AUTOSAR XML (schema 4-0-3)
package /ComponentTypes
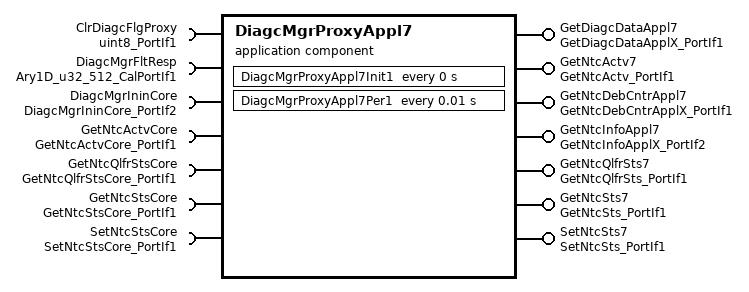
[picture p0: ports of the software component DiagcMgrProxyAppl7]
  application sw component type DiagcMgrProxyAppl7
    7 x provide port, all with server-com-spec{operation=Oper, queue-length=1}:
      GetDiagcDataAppl7: provided-interface=GetDiagcDataApplX_PortIf1
      GetNtcActv7: provided-interface=GetNtcActv_PortIf1
      GetNtcDebCntrAppl7: provided-interface=GetNtcDebCntrApplX_PortIf1
      GetNtcInfoAppl7: provided-interface=GetNtcInfoApplX_PortIf2
      GetNtcQlfrSts7: provided-interface=GetNtcQlfrSts_PortIf1
      GetNtcSts7: provided-interface=GetNtcSts_PortIf1
      SetNtcSts7: provided-interface=SetNtcSts_PortIf1
    7 x require port:
      ClrDiagcFlgProxy: nonqueued-receiver-com-spec{data-element=Val, filter=data-filter-type=ALWAYS, init-value=0}, required-interface=uint8_PortIf1
      DiagcMgrFltResp: parameter-require-com-spec{init-value=[0, 2147487488, 2147487488, 2147487488, 2147487488, 2147487488, 2147487488, 2147487488, 2147487488, 2147487488, 2147487488, 2147487488, 2147487488, 2147487488, 2147487488, 2147487488, 2147487488, 2147487488, 2147487488, 2147487488, 2147487488, 2147487488, 2147487488, 2147487488, 2147487488, 2147487488, 2147487488, 2147487488, 2147487488, 2147487488, 2147487488, 2147487488, 2147487488, 2147487488, 2147487488, 2147487488, 2147487488, 2147487488, 2147487488, 2147487488, 2147487488, 2147487488, 2147487488, 2147487488, 2147487488, 2147487488, 2147487488, 2147487488, 2147487488, 2147487488, 2147487488, 2147487488, 2147487488, 2147487488, 2147487488, 2147487488, 2147487488, 2147487488, 2147487488, 2147487488, 2147487488, 2147487488, 2147487488, 2147487488, 2147487488, 2147487488, 2147487488, 2147487488, 2147487488, 2147487488, 2147487488, 2147487488, 2147487488, 2147487488, 2147487488, 2147487488, 2147487488, 2147487488, 2147487488, 2147487488, 2147487488, 2147487488, 2147487488, 2147487488, 2147487488, 2147487488, 2147487488, 2147487488, 2147487488, 2147487488, 2147487488, 2147487488, 2147487488, 2147487488, 2147487488, 2147487488, 2147487488, 2147487488, 2147487488, 2147487488, 2147487488, 2147487488, 2147487488, 2147487488, 2147487488, 2147487488, 2147487488, 2147487488, 2147487488, 2147487488, 2147487488, 2147487488, 2147487488, 2147487488, 2147487488, 2147487488, 2147487488, 2147487488, 2147487488, 2147487488, 2147487488, 2147487488, 2147487488, 2147487488, 2147487488, 2147487488, 2147487488, 2147487488, 2147487488, 2147487488, 2147487488, 2147487488, 2147487488, 2147487488, 2147487488, 2147487488, 2147487488, 2147487488, 2147487488, 2147487488, 2147487488, 2147487488, 2147487488, 2147487488, 2147487488, 2147487488, 2147487488, 2147487488, 2147487488, 2147487488, 2147487488, 2147487488, 2147487488, 2147487488, 2147487488, 2147487488, 2147487488, 2147487488, 2147487488, 2147487488, 2147487488, 2147487488, 2147487488, 2147487488, 2147487488, 2147487488, 2147487488, 2147487488, 2147487488, 2147487488, 2147487488, 2147487488, 2147487488, 2147487488, 2147487488, 2147487488, 2147487488, 2147487488, 2147487488, 2147487488, 2147487488, 2147487488, 2147487488, 2147487488, 2147487488, 2147487488, 2147487488, 2147487488, 2147487488, 2147487488, 2147487488, 2147487488, 2147487488, 2147487488, 2147487488, 2147487488, 2147487488, 2147487488, 2147487488, 2147487488, 2147487488, 2147487488, 2147487488, 2147487488, 2147487488, 2147487488, 2147487488, 2147487488, 2147487488, 2147487488, 2147487488, 2147487488, 2147487488, 2147487488, 2147487488, 2147487488, 2147487488, 2147487488, 2147487488, 2147487488, 2147487488, 2147487488, 2147487488, 2147487488, 2147487488, 2147487488, 2147487488, 2147487488, 2147487488, 2147487488, 2147487488, 2147487488, 2147487488, 2147487488, 2147487488, 2147487488, 2147487488, 2147487488, 2147487488, 2147487488, 2147487488, 2147487488, 2147487488, 2147487488, 2147487488, 2147487488, 2147487488, 2147487488, 2147487488, 2147487488, 2147487488, 2147487488, 2147487488, 2147487488, 2147487488, 2147487488, 2147487488, 2147487488, 2147487488, 2147487488, 2147487488, 2147487488, 2147487488, 2147487488, 2147487488, 2147487488, 2147487488, 2147487488, 2147487488, 2147487488, 2147487488, 2147487488, 2147487488, 2147487488, 2147487488, 2147487488, 2147487488, 2147487488, 2147487488, 2147487488, 2147487488, 2147487488, 2147487488, 2147487488, 2147487488, 2147487488, 2147487488, 2147487488, 2147487488, 2147487488, 2147487488, 2147487488, 2147487488, 2147487488, 2147487488, 2147487488, 2147487488, 2147487488, 2147487488, 2147487488, 2147487488, 2147487488, 2147487488, 2147487488, 2147487488, 2147487488, 2147487488, 2147487488, 2147487488, 2147487488, 2147487488, 2147487488, 2147487488, 2147487488, 2147487488, 2147487488, 2147487488, 2147487488, 2147487488, 2147487488, 2147487488, 2147487488, 2147487488, 2147487488, 2147487488, 2147487488, 2147487488, 2147487488, 2147487488, 2147487488, 2147487488, 2147487488, 2147487488, 2147487488, 2147487488, 2147487488, 2147487488, 2147487488, 2147487488, 2147487488, 2147487488, 2147487488, 2147487488, 2147487488, 2147487488, 2147487488, 2147487488, 2147487488, 2147487488, 2147487488, 2147487488, 2147487488, 2147487488, 2147487488, 2147487488, 2147487488, 2147487488, 2147487488, 2147487488, 2147487488, 2147487488, 2147487488, 2147487488, 2147487488, 2147487488, 2147487488, 2147487488, 2147487488, 2147487488, 2147487488, 2147487488, 2147487488, 2147487488, 2147487488, 2147487488, 2147487488, 2147487488, 2147487488, 2147487488, 2147487488, 2147487488, 2147487488, 2147487488, 2147487488, 2147487488, 2147487488, 2147487488, 2147487488, 2147487488, 2147487488, 2147487488, 2147487488, 2147487488, 2147487488, 2147487488, 2147487488, 2147487488, 2147487488, 2147487488, 2147487488, 2147487488, 2147487488, 2147487488, 2147487488, 2147487488, 2147487488, 2147487488, 2147487488, 2147487488, 2147487488, 2147487488, 2147487488, 2147487488, 2147487488, 2147487488, 2147487488, 2147487488, 2147487488, 2147487488, 2147487488, 2147487488, 2147487488, 2147487488, 2147487488, 2147487488, 2147487488, 2147487488, 2147487488, 2147487488, 2147487488, 2147487488, 2147487488, 2147487488, 2147487488, 2147487488, 2147487488, 2147487488, 2147487488, 2147487488, 2147487488, 2147487488, 2147487488, 2147487488, 2147487488, 2147487488, 2147487488, 2147487488, 2147487488, 2147487488, 2147487488, 2147487488, 2147487488, 2147487488, 2147487488, 2147487488, 2147487488, 2147487488, 2147487488, 2147487488, 2147487488, 2147487488, 2147487488, 2147487488, 2147487488, 2147487488, 2147487488, 2147487488, 2147487488, 2147487488, 2147487488, 2147487488, 2147487488, 2147487488, 2147487488, 2147487488, 2147487488, 2147487488, 2147487488, 2147487488, 2147487488, 2147487488, 2147487488, 2147487488, 2147487488, 2147487488, 2147487488, 2147487488, 2147487488, 2147487488, 2147487488, 2147487488, 2147487488, 2147487488, 2147487488, 2147487488, 2147487488, 2147487488, 2147487488, 2147487488, 2147487488, 2147487488, 2147487488, 2147487488, 2147487488, 2147487488, 2147487488, 2147487488, 2147487488, 2147487488, 2147487488, 2147487488, 2147487488], parameter=Ary1D}, required-interface=Ary1D_u32_512_CalPortIf1
      DiagcMgrIninCore: required-interface=DiagcMgrIninCore_PortIf2
      GetNtcActvCore: required-interface=GetNtcActvCore_PortIf1
      GetNtcQlfrStsCore: required-interface=GetNtcQlfrStsCore_PortIf1
      GetNtcStsCore: required-interface=GetNtcStsCore_PortIf1
      SetNtcStsCore: required-interface=SetNtcStsCore_PortIf1
    behavior DiagcMgrProxyAppl7_InternalBehavior
      exclusive area DiagcMgrProxyAppl7
      ar-typed-per-instance-memorys:
        5 x data:
          DiagcData7: sw-calibration-access=READ-ONLY, type=DiagcDataRec1
          DiagcMgrNtcInfo7Ary: type=Ary1D_NtcInfoRec4_DiagcMgrProxyAppl7
          DiagcMgrNtcInfo7DebCntrAry: type=Ary1D_s16_DiagcMgrProxyAppl7
          PrevClrNtcFlg7: sw-calibration-access=READ-ONLY, type=uint8
          ProxySetNtcData7: sw-calibration-access=READ-ONLY, type=DiagcDataRec1
      timing event DiagcMgrProxyAppl7_InitEvent: start-on-event=DiagcMgrProxyAppl7Init1, period=0
      timing event TMT_DiagcMgrProxyAppl7Per1: start-on-event=DiagcMgrProxyAppl7Per1, period=0.01
      7 x operation invoked event:
        OIT_GetDiagcDataAppl7_Oper_GetDiagcDataAppl7_Oper: start-on-event=GetDiagcDataAppl7_Oper, operation=GetDiagcDataAppl7.Oper
        OIT_GetNtcActv7_Oper_GetNtcActv7_Oper: start-on-event=GetNtcActv7_Oper, operation=GetNtcActv7.Oper
        OIT_GetNtcDebCntrAppl7_Oper_GetNtcDebCntrAppl7_Oper: start-on-event=GetNtcDebCntrAppl7_Oper, operation=GetNtcDebCntrAppl7.Oper
        OIT_GetNtcInfoAppl7_Oper_GetNtcInfoAppl7_Oper: start-on-event=GetNtcInfoAppl7_Oper, operation=GetNtcInfoAppl7.Oper
        OIT_GetNtcQlfrSts7_Oper_GetNtcQlfrSts7_Oper: start-on-event=GetNtcQlfrSts7_Oper, operation=GetNtcQlfrSts7.Oper
        OIT_GetNtcSts7_Oper_GetNtcSts7_Oper: start-on-event=GetNtcSts7_Oper, operation=GetNtcSts7.Oper
        OIT_SetNtcSts7_Oper_SetNtcSts7_Oper: start-on-event=SetNtcSts7_Oper, operation=SetNtcSts7.Oper
      9 x runnable:
        DiagcMgrProxyAppl7Init1
          sync call SC_DiagcMgrIninCore_Oper: operation=DiagcMgrIninCore.Oper, timeout=0
        DiagcMgrProxyAppl7Per1: can-enter-exclusive-area=DiagcMgrProxyAppl7
          data-receive-point-by-arguments:
            access REC_ClrNtcFlg_Val: accessed-variable=ClrDiagcFlgProxy.Val
        GetDiagcDataAppl7_Oper
        GetNtcActv7_Oper: can-be-invoked-concurrently=true
          sync call SC_GetNtcActvCore_Oper: operation=GetNtcActvCore.Oper, timeout=0
        GetNtcDebCntrAppl7_Oper
        GetNtcInfoAppl7_Oper
        GetNtcQlfrSts7_Oper: can-be-invoked-concurrently=true
          sync call SC_GetNtcQlfrStsCore_Oper: operation=GetNtcQlfrStsCore.Oper, timeout=0
        GetNtcSts7_Oper: can-be-invoked-concurrently=true
          sync call SC_GetNtcStsCore_Oper: operation=GetNtcStsCore.Oper, timeout=0
        SetNtcSts7_Oper: can-be-invoked-concurrently=true
          sync call SC_SetNtcStsCore_Oper: operation=SetNtcStsCore.Oper, timeout=0
  swc implementation DiagcMgrProxyAppl7_Implementation: behavior=DiagcMgrProxyAppl7_InternalBehavior
    code-descriptors:
      code Default: artifact-descriptors=autosar-engineering-object={short-label=Default, category=SWSRC}
